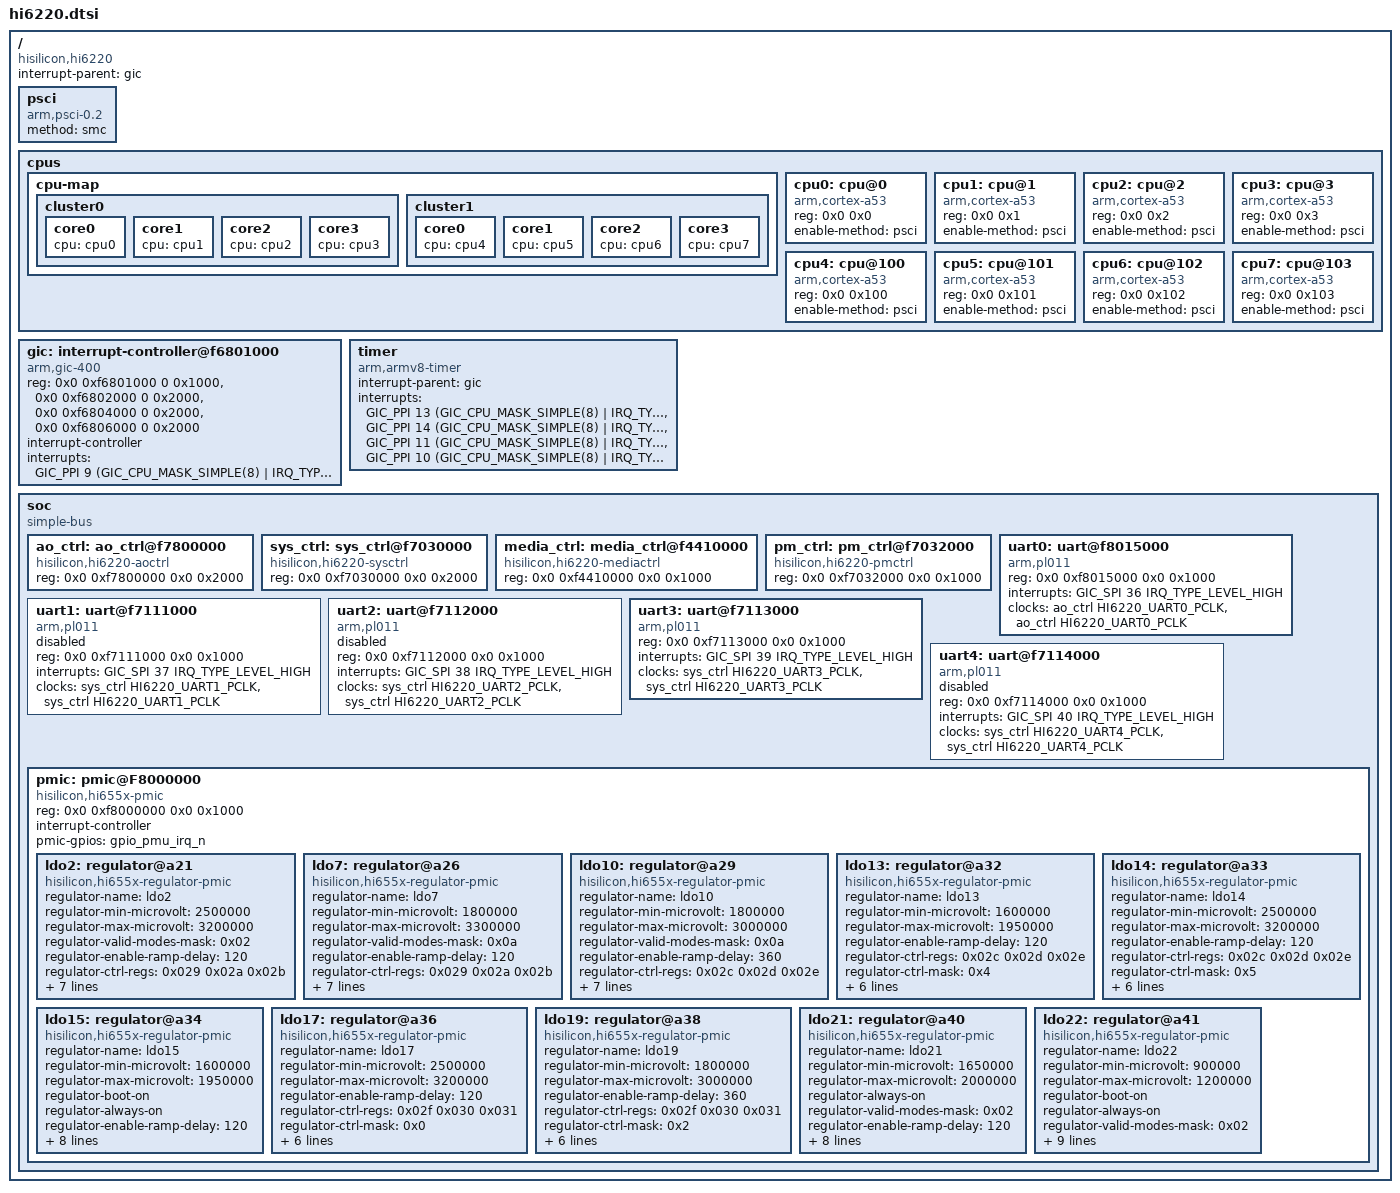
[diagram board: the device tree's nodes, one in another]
/*
 * dts file for Hisilicon Hi6220 SoC
 *
 * Copyright (C) 2015, Hisilicon Ltd.
 */

#include <dt-bindings/interrupt-controller/arm-gic.h>
#include <dt-bindings/clock/hi6220-clock.h>

/ {
	compatible = "hisilicon,hi6220";
	interrupt-parent = <&gic>;
	#address-cells = <2>;
	#size-cells = <2>;

	psci {
		compatible = "arm,psci-0.2";
		method = "smc";
	};

	cpus {
		#address-cells = <2>;
		#size-cells = <0>;

		cpu-map {
			cluster0 {
				core0 {
					cpu = <&cpu0>;
				};
				core1 {
					cpu = <&cpu1>;
				};
				core2 {
					cpu = <&cpu2>;
				};
				core3 {
					cpu = <&cpu3>;
				};
			};
			cluster1 {
				core0 {
					cpu = <&cpu4>;
				};
				core1 {
					cpu = <&cpu5>;
				};
				core2 {
					cpu = <&cpu6>;
				};
				core3 {
					cpu = <&cpu7>;
				};
			};
		};

		cpu0: cpu@0 {
			compatible = "arm,cortex-a53", "arm,armv8";
			device_type = "cpu";
			reg = <0x0 0x0>;
			enable-method = "psci";
		};

		cpu1: cpu@1 {
			compatible = "arm,cortex-a53", "arm,armv8";
			device_type = "cpu";
			reg = <0x0 0x1>;
			enable-method = "psci";
		};

		cpu2: cpu@2 {
			compatible = "arm,cortex-a53", "arm,armv8";
			device_type = "cpu";
			reg = <0x0 0x2>;
			enable-method = "psci";
		};

		cpu3: cpu@3 {
			compatible = "arm,cortex-a53", "arm,armv8";
			device_type = "cpu";
			reg = <0x0 0x3>;
			enable-method = "psci";
		};

		cpu4: cpu@100 {
			compatible = "arm,cortex-a53", "arm,armv8";
			device_type = "cpu";
			reg = <0x0 0x100>;
			enable-method = "psci";
		};

		cpu5: cpu@101 {
			compatible = "arm,cortex-a53", "arm,armv8";
			device_type = "cpu";
			reg = <0x0 0x101>;
			enable-method = "psci";
		};

		cpu6: cpu@102 {
			compatible = "arm,cortex-a53", "arm,armv8";
			device_type = "cpu";
			reg = <0x0 0x102>;
			enable-method = "psci";
		};

		cpu7: cpu@103 {
			compatible = "arm,cortex-a53", "arm,armv8";
			device_type = "cpu";
			reg = <0x0 0x103>;
			enable-method = "psci";
		};
	};

	gic: interrupt-controller@f6801000 {
		compatible = "arm,gic-400";
		reg = <0x0 0xf6801000 0 0x1000>, /* GICD */
		      <0x0 0xf6802000 0 0x2000>, /* GICC */
		      <0x0 0xf6804000 0 0x2000>, /* GICH */
		      <0x0 0xf6806000 0 0x2000>; /* GICV */
		#address-cells = <0>;
		#interrupt-cells = <3>;
		interrupt-controller;
		interrupts = <GIC_PPI 9 (GIC_CPU_MASK_SIMPLE(8) | IRQ_TYPE_LEVEL_HIGH)>;
	};

	timer {
		compatible = "arm,armv8-timer";
		interrupt-parent = <&gic>;
		interrupts = <GIC_PPI 13 (GIC_CPU_MASK_SIMPLE(8) | IRQ_TYPE_LEVEL_LOW)>,
			     <GIC_PPI 14 (GIC_CPU_MASK_SIMPLE(8) | IRQ_TYPE_LEVEL_LOW)>,
			     <GIC_PPI 11 (GIC_CPU_MASK_SIMPLE(8) | IRQ_TYPE_LEVEL_LOW)>,
			     <GIC_PPI 10 (GIC_CPU_MASK_SIMPLE(8) | IRQ_TYPE_LEVEL_LOW)>;
	};

	soc {
		compatible = "simple-bus";
		#address-cells = <2>;
		#size-cells = <2>;
		ranges;

		ao_ctrl: ao_ctrl@f7800000 {
			compatible = "hisilicon,hi6220-aoctrl", "syscon";
			reg = <0x0 0xf7800000 0x0 0x2000>;
			#clock-cells = <1>;
		};

		sys_ctrl: sys_ctrl@f7030000 {
			compatible = "hisilicon,hi6220-sysctrl", "syscon";
			reg = <0x0 0xf7030000 0x0 0x2000>;
			#clock-cells = <1>;
		};

		media_ctrl: media_ctrl@f4410000 {
			compatible = "hisilicon,hi6220-mediactrl", "syscon";
			reg = <0x0 0xf4410000 0x0 0x1000>;
			#clock-cells = <1>;
		};

		pm_ctrl: pm_ctrl@f7032000 {
			compatible = "hisilicon,hi6220-pmctrl", "syscon";
			reg = <0x0 0xf7032000 0x0 0x1000>;
			#clock-cells = <1>;
		};

		uart0: uart@f8015000 {	/* console */
			compatible = "arm,pl011", "arm,primecell";
			reg = <0x0 0xf8015000 0x0 0x1000>;
			interrupts = <GIC_SPI 36 IRQ_TYPE_LEVEL_HIGH>;
			clocks = <&ao_ctrl HI6220_UART0_PCLK>,
				 <&ao_ctrl HI6220_UART0_PCLK>;
			clock-names = "uartclk", "apb_pclk";
		};

		uart1: uart@f7111000 {
			compatible = "arm,pl011", "arm,primecell";
			reg = <0x0 0xf7111000 0x0 0x1000>;
			interrupts = <GIC_SPI 37 IRQ_TYPE_LEVEL_HIGH>;
			clocks = <&sys_ctrl HI6220_UART1_PCLK>,
				 <&sys_ctrl HI6220_UART1_PCLK>;
			clock-names = "uartclk", "apb_pclk";
			status = "disabled";
		};

		uart2: uart@f7112000 {
			compatible = "arm,pl011", "arm,primecell";
			reg = <0x0 0xf7112000 0x0 0x1000>;
			interrupts = <GIC_SPI 38 IRQ_TYPE_LEVEL_HIGH>;
			clocks = <&sys_ctrl HI6220_UART2_PCLK>,
				 <&sys_ctrl HI6220_UART2_PCLK>;
			clock-names = "uartclk", "apb_pclk";
			status = "disabled";
		};

		uart3: uart@f7113000 {
			compatible = "arm,pl011", "arm,primecell";
			reg = <0x0 0xf7113000 0x0 0x1000>;
			interrupts = <GIC_SPI 39 IRQ_TYPE_LEVEL_HIGH>;
			clocks = <&sys_ctrl HI6220_UART3_PCLK>,
				 <&sys_ctrl HI6220_UART3_PCLK>;
			clock-names = "uartclk", "apb_pclk";
		};

		uart4: uart@f7114000 {
			compatible = "arm,pl011", "arm,primecell";
			reg = <0x0 0xf7114000 0x0 0x1000>;
			interrupts = <GIC_SPI 40 IRQ_TYPE_LEVEL_HIGH>;
			clocks = <&sys_ctrl HI6220_UART4_PCLK>,
				 <&sys_ctrl HI6220_UART4_PCLK>;
			clock-names = "uartclk", "apb_pclk";
			status = "disabled";
		};
		pmic: pmic@F8000000 {
			compatible = "hisilicon,hi655x-pmic";
			reg = <0x0 0xf8000000 0x0 0x1000>;
			#interrupt-cells = <2>;
			interrupt-controller;
			pmic-gpios = <&gpio_pmu_irq_n>;
			status = "okay";
			ldo2: regulator@a21 {
				compatible = "hisilicon,hi655x-regulator-pmic";
				regulator-name = "ldo2";
				regulator-min-microvolt = <2500000>;
				regulator-max-microvolt = <3200000>;
				regulator-valid-modes-mask = <0x02>;
				regulator-enable-ramp-delay = <120>;
				regulator-ctrl-regs = <0x029 0x02a 0x02b>;
				regulator-ctrl-mask = <0x1>;
				regulator-vset-regs = <0x072>;
				regulator-vset-mask = <0x7>;
				regulator-n-vol = <8>;
				regulator-vset-table  = <2500000>,<2600000>,
							<2700000>,<2800000>,
							<2900000>,<3000000>,
							<3100000>,<3200000>;
			};
			ldo7: regulator@a26 {
				compatible = "hisilicon,hi655x-regulator-pmic";
				regulator-name = "ldo7";
				regulator-min-microvolt = <1800000>;
				regulator-max-microvolt = <3300000>;
				regulator-valid-modes-mask = <0x0a>;
				regulator-enable-ramp-delay = <120>;
				regulator-ctrl-regs = <0x029 0x02a 0x02b>;
				regulator-ctrl-mask = <0x6>;
				regulator-vset-regs = <0x078>;
				regulator-vset-mask = <0x7>;
				regulator-n-vol = <8>;
				regulator-vset-table  = <1800000>,<1850000>,
							<2850000>,<2900000>,
							<3000000>,<3100000>,
							<3200000>,<3300000>;
			};
			ldo10: regulator@a29 {
				compatible = "hisilicon,hi655x-regulator-pmic";
				regulator-name = "ldo10";
				regulator-min-microvolt = <1800000>;
				regulator-max-microvolt = <3000000>;
				regulator-valid-modes-mask = <0x0a>;
				regulator-enable-ramp-delay = <360>;
				regulator-ctrl-regs = <0x02c 0x02d 0x02e>;
				regulator-ctrl-mask = <0x1>;
				regulator-vset-regs = <0x07b>;
				regulator-vset-mask = <0x7>;
				regulator-n-vol = <8>;
				regulator-vset-table  = <1800000>,<1850000>,
							<1900000>,<2750000>,
							<2800000>,<2850000>,
							<2900000>,<3000000>;
			};
			ldo13: regulator@a32 {
				compatible = "hisilicon,hi655x-regulator-pmic";
				regulator-name = "ldo13";
				regulator-min-microvolt = <1600000>;
				regulator-max-microvolt = <1950000>;
				regulator-enable-ramp-delay = <120>;
				regulator-ctrl-regs = <0x02c 0x02d 0x02e>;
				regulator-ctrl-mask = <0x4>;
				regulator-vset-regs = <0x07e>;
				regulator-vset-mask = <0x7>;
				regulator-n-vol = <8>;
				regulator-vset-table  = <1600000>,<1650000>,
							<1700000>,<1750000>,
							<1800000>,<1850000>,
							<1900000>,<1950000>;
			};
			ldo14: regulator@a33 {
				compatible = "hisilicon,hi655x-regulator-pmic";
				regulator-name = "ldo14";
				regulator-min-microvolt = <2500000>;
				regulator-max-microvolt = <3200000>;
				regulator-enable-ramp-delay = <120>;
				regulator-ctrl-regs = <0x02c 0x02d 0x02e>;
				regulator-ctrl-mask = <0x5>;
				regulator-vset-regs = <0x07f>;
				regulator-vset-mask = <0x7>;
				regulator-n-vol = <8>;
				regulator-vset-table  = <2500000>,<2600000>,
							<2700000>,<2800000>,
							<2900000>,<3000000>,
							<3100000>,<3200000>;
			};
			ldo15: regulator@a34 {
				compatible = "hisilicon,hi655x-regulator-pmic";
				regulator-name = "ldo15";
				regulator-min-microvolt = <1600000>;
				regulator-max-microvolt = <1950000>;
				regulator-boot-on;
				regulator-always-on;
				regulator-enable-ramp-delay = <120>;
				regulator-ctrl-regs = <0x02c 0x02d 0x02e>;
				regulator-ctrl-mask = <0x6>;
				regulator-vset-regs = <0x080>;
				regulator-vset-mask = <0x7>;
				regulator-n-vol = <8>;
				regulator-vset-table  = <1600000>,<1650000>,
							<1700000>,<1750000>,
							<1800000>,<1850000>,
							<1900000>,<1950000>;
			};
			ldo17: regulator@a36 {
				compatible = "hisilicon,hi655x-regulator-pmic";
				regulator-name = "ldo17";
				regulator-min-microvolt = <2500000>;
				regulator-max-microvolt = <3200000>;
				regulator-enable-ramp-delay = <120>;
				regulator-ctrl-regs = <0x02f 0x030 0x031>;
				regulator-ctrl-mask = <0x0>;
				regulator-vset-regs = <0x082>;
				regulator-vset-mask = <0x7>;
				regulator-n-vol = <8>;
				regulator-vset-table  = <2500000>,<2600000>,
							<2700000>,<2800000>,
							<2900000>,<3000000>,
							<3100000>,<3200000>;
			};
			ldo19: regulator@a38 {
				compatible = "hisilicon,hi655x-regulator-pmic";
				regulator-name = "ldo19";
				regulator-min-microvolt = <1800000>;
				regulator-max-microvolt = <3000000>;
				regulator-enable-ramp-delay = <360>;
				regulator-ctrl-regs = <0x02f 0x030 0x031>;
				regulator-ctrl-mask = <0x2>;
				regulator-vset-regs = <0x084>;
				regulator-vset-mask = <0x7>;
				regulator-n-vol = <8>;
				regulator-vset-table  = <1800000>,<1850000>,
							<1900000>,<2750000>,
							<2800000>,<2850000>,
							<2900000>,<3000000>;
			};
			ldo21: regulator@a40 {
				compatible = "hisilicon,hi655x-regulator-pmic";
				regulator-name = "ldo21";
				regulator-min-microvolt = <1650000>;
				regulator-max-microvolt = <2000000>;
				regulator-always-on;
				regulator-valid-modes-mask = <0x02>;
				regulator-enable-ramp-delay = <120>;
				regulator-ctrl-regs = <0x02f 0x030 0x031>;
				regulator-ctrl-mask = <0x4>;
				regulator-vset-regs = <0x086>;
				regulator-vset-mask = <0x7>;
				regulator-n-vol = <8>;
				regulator-vset-table  = <1650000>,<1700000>,
							<1750000>,<1800000>,
							<1850000>,<1900000>,
							<1950000>,<2000000>;
			};
			ldo22: regulator@a41 {
				compatible = "hisilicon,hi655x-regulator-pmic";
				regulator-name = "ldo22";
				regulator-min-microvolt = <900000>;
				regulator-max-microvolt = <1200000>;
				regulator-boot-on;
				regulator-always-on;
				regulator-valid-modes-mask = <0x02>;
				regulator-enable-ramp-delay = <120>;
				regulator-ctrl-regs = <0x02f 0x030 0x031>;
				regulator-ctrl-mask = <0x5>;
				regulator-vset-regs = <0x087>;
				regulator-vset-mask = <0x7>;
				regulator-n-vol = <8>;
				regulator-vset-table  = <900000>,<1000000>,
							<1050000>,<1100000>,
							<1150000>,<1175000>,
							<1185000>,<1200000>;
			       };
		};
	};
};
